# CIU32L051 register map
File version: 1.0.0
Registers are 32-bit, read-write, reset 0x0 unless marked. A register's access mark holds for its fields unless they carry their own. Offsets are from the block's base; [hi:lo] are bit positions; {n}, {i} and the like mark numbered series.

## RTC
Base 0x40002800
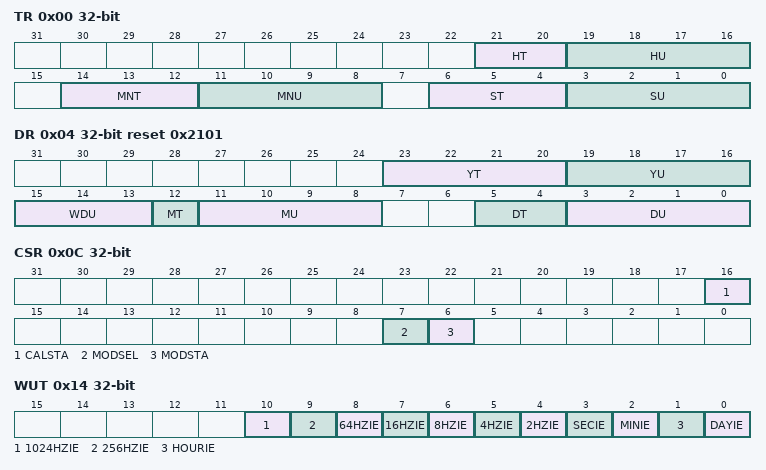
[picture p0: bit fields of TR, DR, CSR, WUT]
0x00 TR
  [21:20] HT, [19:16] HU, [14:12] MNT, [11:8] MNU, [6:4] ST, [3:0] SU
0x04 DR reset 0x2101
  [23:20] YT, [19:16] YU, [15:13] WDU, [12] MT, [11:8] MU, [5:4] DT, [3:0] DU
0x08 SSR
  [7:0] SS
0x0C CSR
  [16] CALSTA, [7] MODSEL, [6] MODSTA
0x14 WUT
  [10] 1024HZIE, [9] 256HZIE, [8] 64HZIE, [7] 16HZIE, [6] 8HZIE, [5] 4HZIE, [4] 2HZIE, [3] SECIE, [2] MINIE, [1] HOURIE, [0] DAYIE
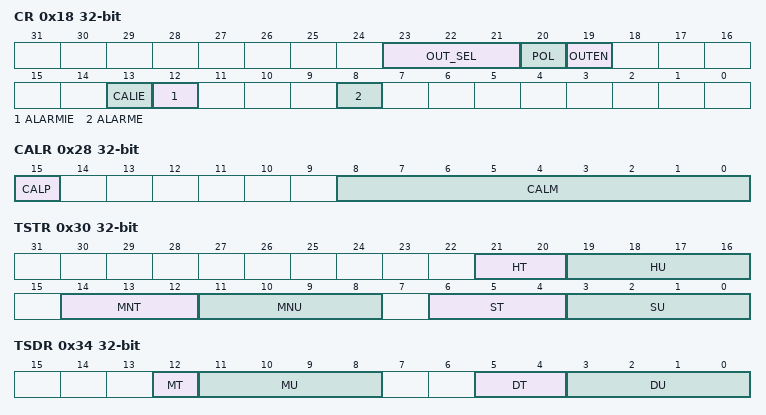
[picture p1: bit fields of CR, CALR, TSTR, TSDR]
0x18 CR
  [23:21] OUT_SEL, [20] POL, [19] OUTEN, [13] CALIE, [12] ALARMIE, [8] ALARME
0x24 WPR
  [7:0] KEY
0x28 CALR
  [15] CALP, [8:0] CALM
0x30 TSTR
  [21:20] HT, [19:16] HU, [14:12] MNT, [11:8] MNU, [6:4] ST, [3:0] SU
0x34 TSDR
  [12] MT, [11:8] MU, [5:4] DT, [3:0] DU
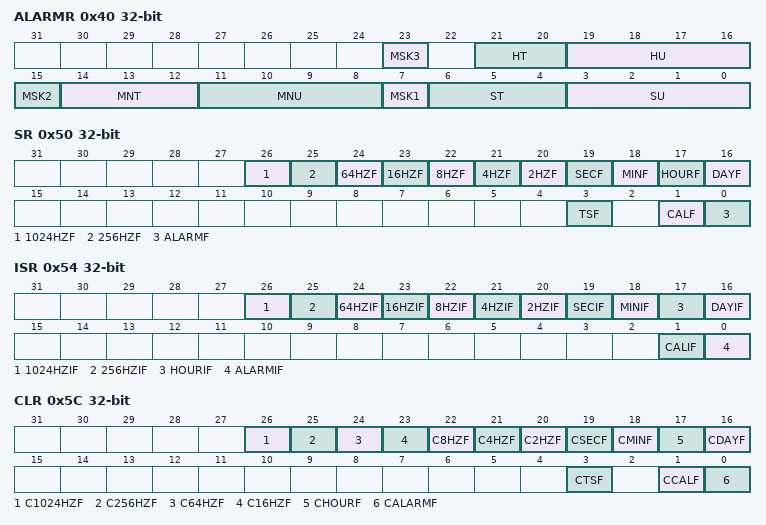
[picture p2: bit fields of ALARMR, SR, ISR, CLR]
0x40 ALARMR
  [23] MSK3, [21:20] HT, [19:16] HU, [15] MSK2, [14:12] MNT, [11:8] MNU, [7] MSK1, [6:4] ST, [3:0] SU
0x50 SR
  [26] 1024HZF, [25] 256HZF, [24] 64HZF, [23] 16HZF, [22] 8HZF, [21] 4HZF, [20] 2HZF, [19] SECF, [18] MINF, [17] HOURF, [16] DAYF, [3] TSF, [1] CALF, [0] ALARMF
0x54 ISR
  [26] 1024HZIF, [25] 256HZIF, [24] 64HZIF, [23] 16HZIF, [22] 8HZIF, [21] 4HZIF, [20] 2HZIF, [19] SECIF, [18] MINIF, [17] HOURIF, [16] DAYIF, [1] CALIF, [0] ALARMIF
0x5C CLR
  [26] C1024HZF, [25] C256HZF, [24] C64HZF, [23] C16HZF, [22] C8HZF, [21] C4HZF, [20] C2HZF, [19] CSECF, [18] CMINF, [17] CHOURF, [16] CDAYF, [3] CTSF, [1] CCALF, [0] CALARMF

## SCB
Base 0xE0000000
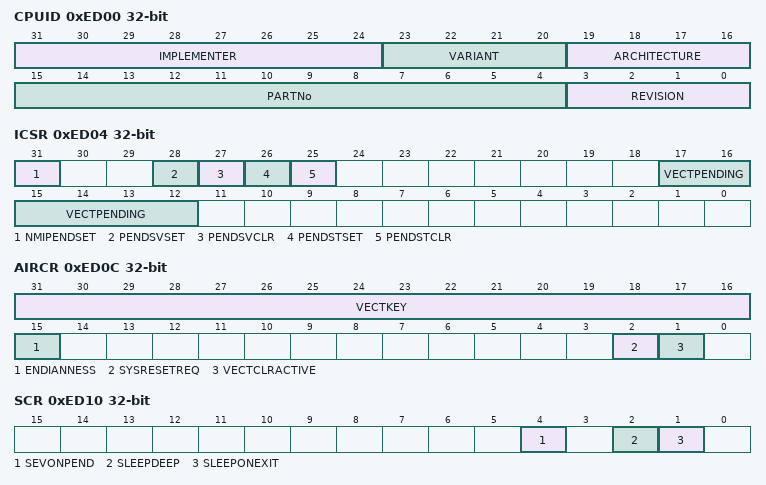
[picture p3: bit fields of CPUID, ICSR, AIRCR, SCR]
0xED00 CPUID
  [31:24] IMPLEMENTER, [23:20] VARIANT, [19:16] ARCHITECTURE, [15:4] PARTNo, [3:0] REVISION
0xED04 ICSR
  [31] NMIPENDSET, [28] PENDSVSET, [27] PENDSVCLR, [26] PENDSTSET, [25] PENDSTCLR, [17:12] VECTPENDING
0xED08 VTOR
  [31:7] TBLOFF
0xED0C AIRCR
  [31:16] VECTKEY, [15] ENDIANNESS, [2] SYSRESETREQ, [1] VECTCLRACTIVE
0xED10 SCR
  [4] SEVONPEND, [2] SLEEPDEEP, [1] SLEEPONEXIT
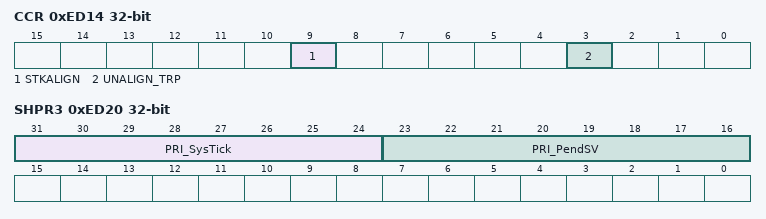
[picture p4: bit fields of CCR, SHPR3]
0xED14 CCR
  [9] STKALIGN, [3] UNALIGN_TRP
0xED1C SHPR2
  [31:24] PRI_SVCall
0xED20 SHPR3
  [31:24] PRI_SysTick, [23:16] PRI_PendSV
0xED24 SHCSR
  [15] SECALLPENDED

## SPI1
Base 0x40013000
Same registers: SPI2 0x40003800
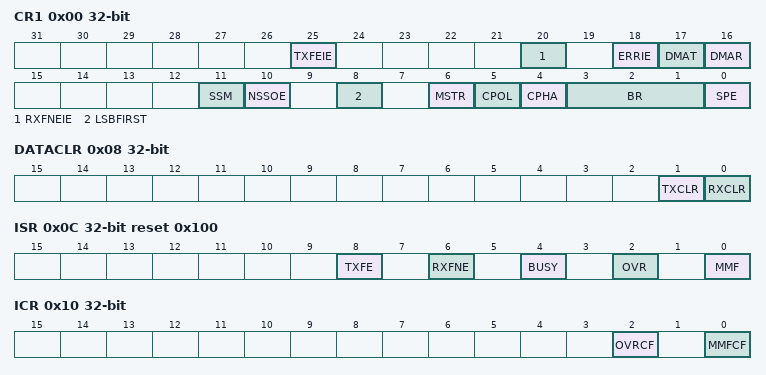
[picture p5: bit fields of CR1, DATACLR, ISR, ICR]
0x00 CR1
  [25] TXFEIE, [20] RXFNEIE, [18] ERRIE, [17] DMAT, [16] DMAR, [11] SSM, [10] NSSOE, [8] LSBFIRST, [6] MSTR, [5] CPOL, [4] CPHA, [3:1] BR, [0] SPE
0x04 CR2 reset 0x1
  [0] NSSO
0x08 DATACLR
  [1] TXCLR, [0] RXCLR
0x0C ISR reset 0x100
  [8] TXFE, [6] RXFNE, [4] BUSY, [2] OVR, [0] MMF
0x10 ICR
  [2] OVRCF, [0] MMFCF
0x14 DR
  [7:0] DR

## SYSCFG
Base 0x40010000
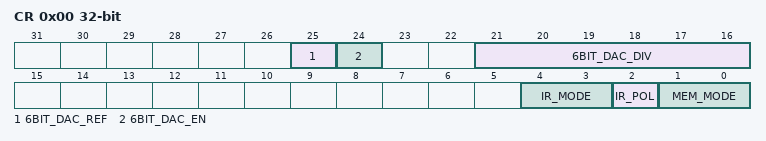
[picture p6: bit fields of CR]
0x00 CR
  [25] 6BIT_DAC_REF, [24] 6BIT_DAC_EN, [21:16] 6BIT_DAC_DIV, [4:3] IR_MODE, [2] IR_POL, [1:0] MEM_MODE
0x04 SECCR
  [5] PVD_LOCK

## SYSTICK
Base 0xE000E010
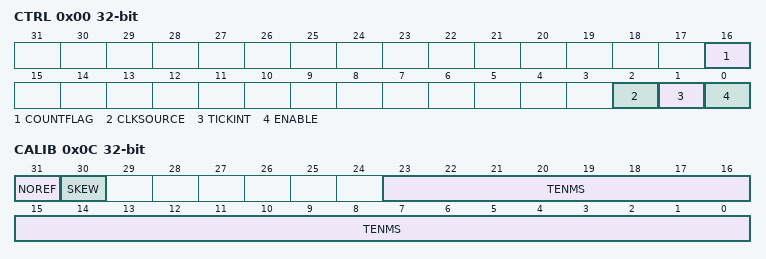
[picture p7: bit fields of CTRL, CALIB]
0x00 CTRL
  [16] COUNTFLAG, [2] CLKSOURCE, [1] TICKINT, [0] ENABLE
0x04 LOAD
  [23:0] RELOAD
0x08 VAL
  [23:0] CURRENT
0x0C CALIB
  [31] NOREF, [30] SKEW, [23:0] TENMS

## TAMP
Base 0x4000B000
0x00 ENR
  [0] TAMPEN
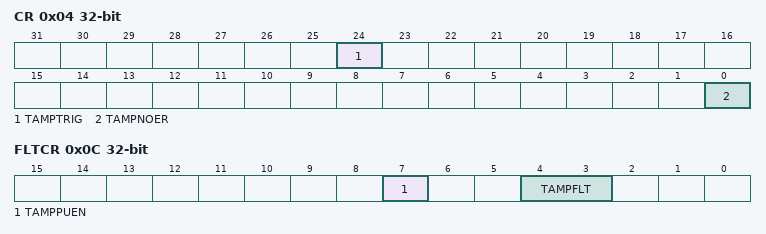
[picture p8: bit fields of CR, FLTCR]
0x04 CR
  [24] TAMPTRIG, [0] TAMPNOER
0x0C FLTCR
  [7] TAMPPUEN, [4:3] TAMPFLT
0x2C IER
  [0] TAMPIE
0x30 SR
  [0] TAMPF
0x34 ISR
  [0] TAMPIF
0x3C CLR
  [0] CTAMPF
{0x100+4i} BKP{i}R (i=0..4)
  [31:0] BKP

## TIM3
Base 0x40000400
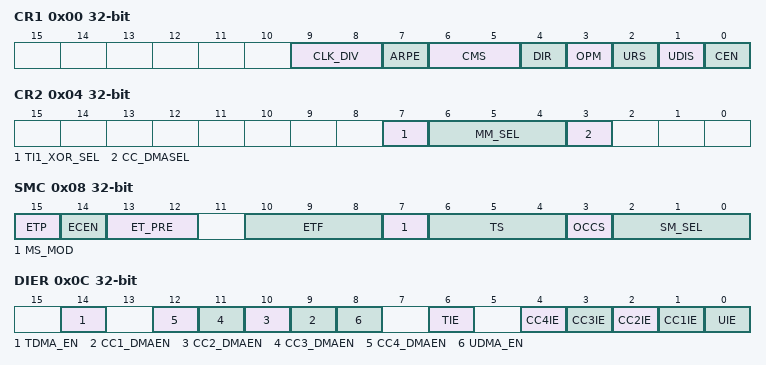
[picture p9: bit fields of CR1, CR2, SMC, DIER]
0x00 CR1
  [9:8] CLK_DIV, [7] ARPE, [6:5] CMS, [4] DIR, [3] OPM, [2] URS, [1] UDIS, [0] CEN
0x04 CR2
  [7] TI1_XOR_SEL, [6:4] MM_SEL, [3] CC_DMASEL
0x08 SMC
  [15] ETP, [14] ECEN, [13:12] ET_PRE, [10:8] ETF, [7] MS_MOD, [6:4] TS, [3] OCCS, [2:0] SM_SEL
0x0C DIER
  [14] TDMA_EN, [n+8] CC{n}_DMAEN (n=1..4), [8] UDMA_EN, [6] TIE, [n] CC{n}IE (n=1..4), [0] UIE
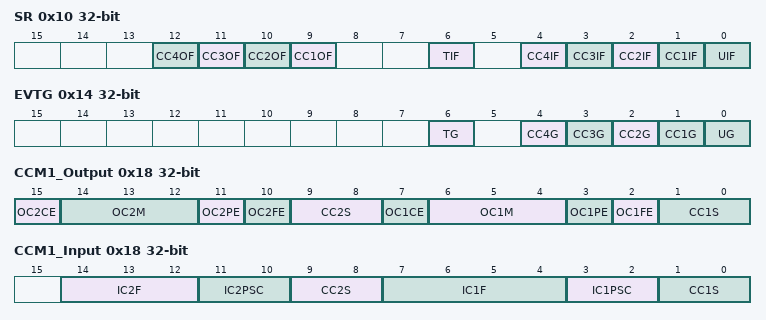
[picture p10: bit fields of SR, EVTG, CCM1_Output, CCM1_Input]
0x10 SR
  [n+8] CC{n}OF (n=1..4), [6] TIF, [n] CC{n}IF (n=1..4), [0] UIF
0x14 EVTG
  [6] TG, [n] CC{n}G (n=1..4), [0] UG
0x18 CCM1_Output
  [15] OC2CE, [14:12] OC2M, [11] OC2PE, [10] OC2FE, [9:8] CC2S, [7] OC1CE, [6:4] OC1M, [3] OC1PE, [2] OC1FE, [1:0] CC1S
0x18 CCM1_Input (alternate view of CCM1_Output)
  [14:12] IC2F, [11:10] IC2PSC, [9:8] CC2S, [7:4] IC1F, [3:2] IC1PSC, [1:0] CC1S
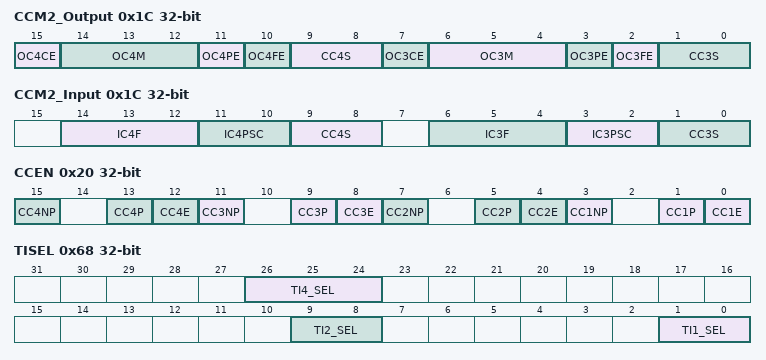
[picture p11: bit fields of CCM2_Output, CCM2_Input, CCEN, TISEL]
0x1C CCM2_Output
  [15] OC4CE, [14:12] OC4M, [11] OC4PE, [10] OC4FE, [9:8] CC4S, [7] OC3CE, [6:4] OC3M, [3] OC3PE, [2] OC3FE, [1:0] CC3S
0x1C CCM2_Input (alternate view of CCM2_Output)
  [14:12] IC4F, [11:10] IC4PSC, [9:8] CC4S, [6:4] IC3F, [3:2] IC3PSC, [1:0] CC3S
0x20 CCEN
  [4n-1] CC{n}NP (n=1..4), [4n-3] CC{n}P (n=1..4), [4n-4] CC{n}E (n=1..4)
0x24 CNT
  [15:0] CNT
0x28 PSC
  [15:0] PSC
0x2C ARR reset 0xFFFF
  [15:0] ARR
{0x30+4i} CC{i} (i=1..4)
  [15:0] CC{i}
0x50 CFG
  [0] OCREF_CLR
0x60 AF1
  [16:14] ETR_SEL
0x68 TISEL
  [26:24] TI4_SEL, [9:8] TI2_SEL, [1:0] TI1_SEL

## TIM4
Base 0x40000800
Same registers: TIM5 0x40000C00
Registers as TIM3; these are added or differ:
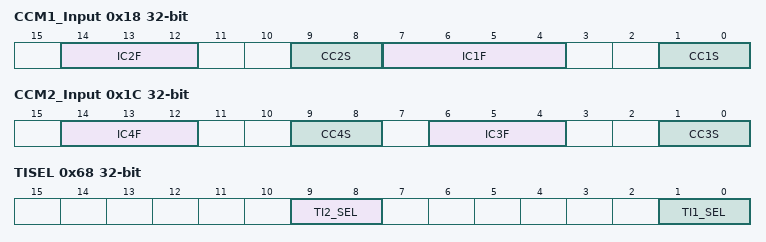
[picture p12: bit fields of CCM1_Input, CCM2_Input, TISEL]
0x18 CCM1_Input (alternate view of CCM1_Output)
  [14:12] IC2F, [9:8] CC2S, [7:4] IC1F, [1:0] CC1S
0x1C CCM2_Input (alternate view of CCM2_Output)
  [14:12] IC4F, [9:8] CC4S, [6:4] IC3F, [1:0] CC3S
0x68 TISEL
  [9:8] TI2_SEL, [1:0] TI1_SEL

## TIM8
Base 0x40001000
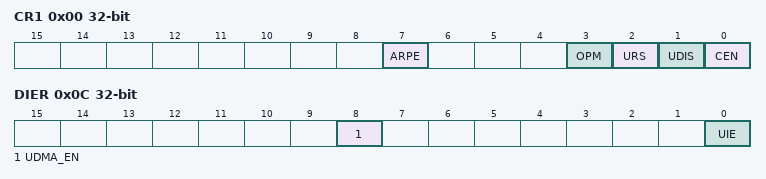
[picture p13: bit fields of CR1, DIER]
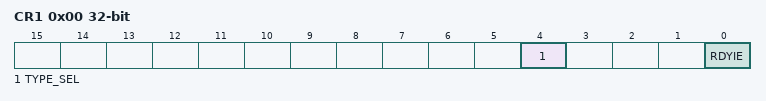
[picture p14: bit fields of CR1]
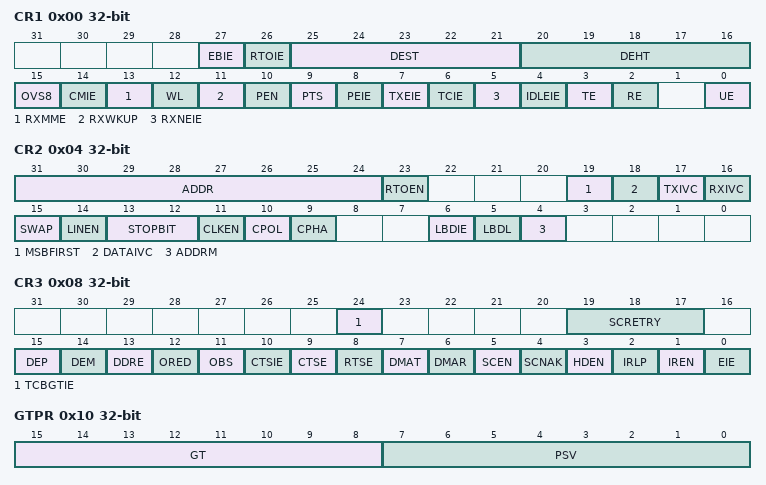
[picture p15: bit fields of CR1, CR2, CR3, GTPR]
0x00 CR1
  [7] ARPE, [3] OPM, [2] URS, [1] UDIS, [0] CEN
0x04 CR2
  [6:4] MM_SEL
0x0C DIER
  [8] UDMA_EN, [0] UIE
0x10 SR
  [0] UIF
0x14 EVTG
  [0] UG
0x24 CNT
  [15:0] CNT
0x28 PSC
  [15:0] PSC
0x2C ARR reset 0xFFFF
  [15:0] ARR

## TRNG
Base 0x40018000
0x00 CR1
  [4] TYPE_SEL, [0] RDYIE
0x08 SR
  [0] RDY
0x10 DR
  [31:0] OUT

## USART1
Base 0x40013800
0x00 CR1
  [27] EBIE, [26] RTOIE, [25:21] DEST, [20:16] DEHT, [15] OVS8, [14] CMIE, [13] RXMME, [12] WL, [11] RXWKUP, [10] PEN, [9] PTS, [8] PEIE, [7] TXEIE, [6] TCIE, [5] RXNEIE, [4] IDLEIE, [3] TE, [2] RE, [0] UE
0x04 CR2
  [31:24] ADDR, [23] RTOEN, [19] MSBFIRST, [18] DATAIVC, [17] TXIVC, [16] RXIVC, [15] SWAP, [14] LINEN, [13:12] STOPBIT, [11] CLKEN, [10] CPOL, [9] CPHA, [6] LBDIE, [5] LBDL, [4] ADDRM
0x08 CR3
  [24] TCBGTIE, [19:17] SCRETRY, [15] DEP, [14] DEM, [13] DDRE, [12] ORED, [11] OBS, [10] CTSIE, [9] CTSE, [8] RTSE, [7] DMAT, [6] DMAR, [5] SCEN, [4] SCNAK, [3] HDEN, [2] IRLP, [1] IREN, [0] EIE
0x0C BRR
  [15:0] BRR
0x10 GTPR
  [15:8] GT, [7:0] PSV
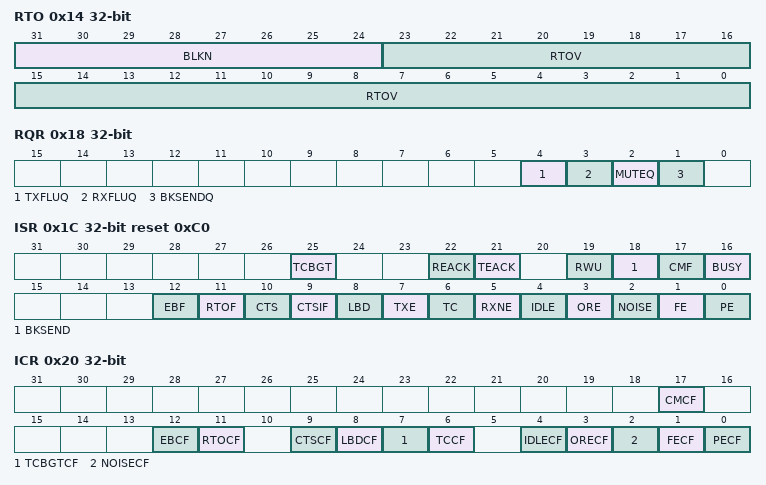
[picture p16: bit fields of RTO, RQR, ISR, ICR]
0x14 RTO
  [31:24] BLKN, [23:0] RTOV
0x18 RQR
  [4] TXFLUQ, [3] RXFLUQ, [2] MUTEQ, [1] BKSENDQ
0x1C ISR reset 0xC0
  [25] TCBGT, [22] REACK, [21] TEACK, [19] RWU, [18] BKSEND, [17] CMF, [16] BUSY, [12] EBF, [11] RTOF, [10] CTS, [9] CTSIF, [8] LBD, [7] TXE, [6] TC, [5] RXNE, [4] IDLE, [3] ORE, [2] NOISE, [1] FE, [0] PE
0x20 ICR
  [17] CMCF, [12] EBCF, [11] RTOCF, [9] CTSCF, [8] LBDCF, [7] TCBGTCF, [6] TCCF, [4] IDLECF, [3] ORECF, [2] NOISECF, [1] FECF, [0] PECF
0x24 RDR
  [8:0] RDR
0x28 TDR
  [8:0] TDR

## UART2
Base 0x40004400
Same registers: UART3 0x40004800, UART4 0x40004C00
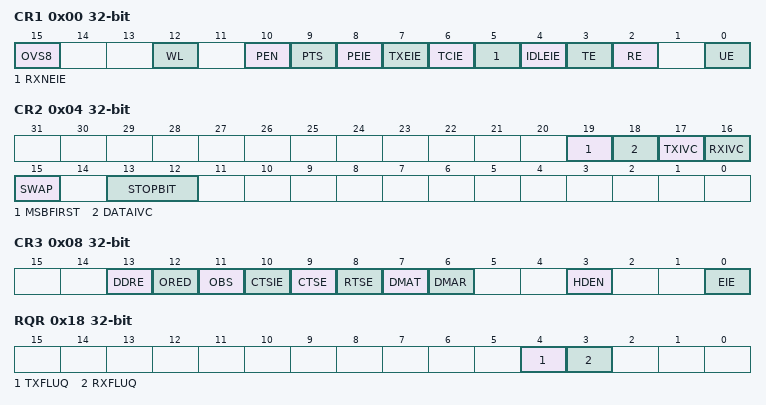
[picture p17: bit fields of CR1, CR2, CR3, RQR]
0x00 CR1
  [15] OVS8, [12] WL, [10] PEN, [9] PTS, [8] PEIE, [7] TXEIE, [6] TCIE, [5] RXNEIE, [4] IDLEIE, [3] TE, [2] RE, [0] UE
0x04 CR2
  [19] MSBFIRST, [18] DATAIVC, [17] TXIVC, [16] RXIVC, [15] SWAP, [13:12] STOPBIT
0x08 CR3
  [13] DDRE, [12] ORED, [11] OBS, [10] CTSIE, [9] CTSE, [8] RTSE, [7] DMAT, [6] DMAR, [3] HDEN, [0] EIE
0x0C BRR
  [15:0] BRR
0x18 RQR
  [4] TXFLUQ, [3] RXFLUQ
0x1C ISR reset 0xC0
  [22] REACK, [21] TEACK, [16] BUSY, [10] CTS, [9] CTSIF, [7] TXE, [6] TC, [5] RXNE, [3] ORE, [2] NOISE, [1] FE, [0] PE
0x20 ICR
  [9] CTSCF, [6] TCCF, [3] ORECF, [2] NOISECF, [1] FECF, [0] PECF
0x24 RDR
  [8:0] RDR
0x28 TDR
  [8:0] TDR

## VREFBUF
Base 0x400101B0
0x00 CSR
  [4] RDY, [3:2] VRS, [0] EN

## WWDG
Base 0x40002C00
0x00 CR
  [7] WDGEN, [6:0] CNT
0x04 CFG reset 0x3800
  [13:11] WDGPR, [9] EWI, [6:0] WIN
0x08 SR
  [0] EWIF
